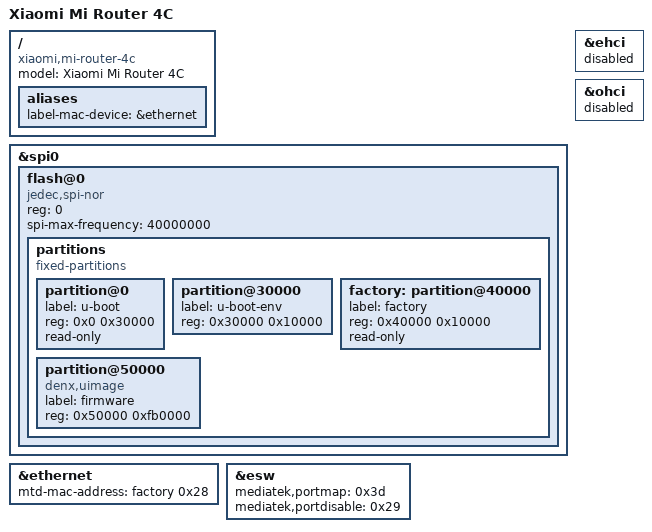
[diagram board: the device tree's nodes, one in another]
// SPDX-License-Identifier: GPL-2.0-or-later OR MIT

#include "mt7628an_xiaomi_mi-router-4.dtsi"

/ {
	compatible = "xiaomi,mi-router-4c", "mediatek,mt7628an-soc";
	model = "Xiaomi Mi Router 4C";

	aliases {
		label-mac-device = &ethernet;
	};
};

&spi0 {
	status = "okay";

	flash@0 {
		compatible = "jedec,spi-nor";
		reg = <0>;
		spi-max-frequency = <40000000>;

		partitions {
			compatible = "fixed-partitions";
			#address-cells = <1>;
			#size-cells = <1>;

			partition@0 {
				label = "u-boot";
				reg = <0x0 0x30000>;
				read-only;
			};

			partition@30000 {
				label = "u-boot-env";
				reg = <0x30000 0x10000>;
			};

			factory: partition@40000 {
				label = "factory";
				reg = <0x40000 0x10000>;
				read-only;
			};

			partition@50000 {
				compatible = "denx,uimage";
				label = "firmware";
				reg = <0x50000 0xfb0000>;
			};
		};
	};
};

&ehci {
	status = "disabled";
};

&ohci {
	status = "disabled";
};

&ethernet {
	mtd-mac-address = <&factory 0x28>;
};

&esw {
	mediatek,portmap = <0x3d>;
	mediatek,portdisable = <0x29>;
};
